VERSION "HIPBNYYYYYYYYYYYYYYYYYYYYYYYYYYYYYYYYYYYYY/4/%%%/4/'%**4YYY///"

NS_ :

BS_:

BU_: GTW IMU TMS SCH BMS0 BMS1 BMS2 BMS3 BMS4 BMS5 BMS6

BO_ 16 GTW_requests: 1 GTW
 SG_ transmit_request : 0|1@1+ (1,0) [0|0] ""  BMS0
 SG_ BMS_state_request : 1|1@1+ (1,0) [0|0] ""  BMS0

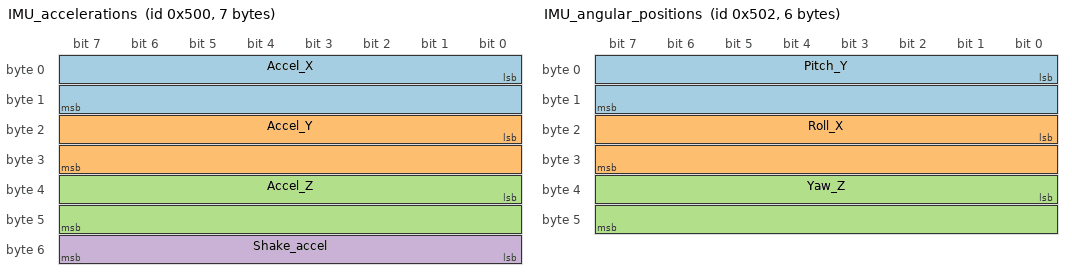
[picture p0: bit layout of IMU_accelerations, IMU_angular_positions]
BO_ 1280 IMU_accelerations: 7 IMU
 SG_ Accel_X : 0|16@1- (1,0) [-2000|2000] "mG"  GTW
 SG_ Accel_Y : 16|16@1- (1,0) [-2000|2000] "mG"  GTW
 SG_ Accel_Z : 32|16@1- (1,0) [-2000|2000] "mG"  GTW
 SG_ Shake_accel : 48|8@1+ (1,0) [0|1] ""  GTW

BO_ 1282 IMU_angular_positions: 6 IMU
 SG_ Pitch_Y : 0|16@1- (1,0) [-180|180] "Degrees"  GTW
 SG_ Roll_X : 16|16@1- (1,0) [-90|90] "Degrees"  GTW
 SG_ Yaw_Z : 32|16@1+ (1,0) [0|360] "Degrees"  GTW

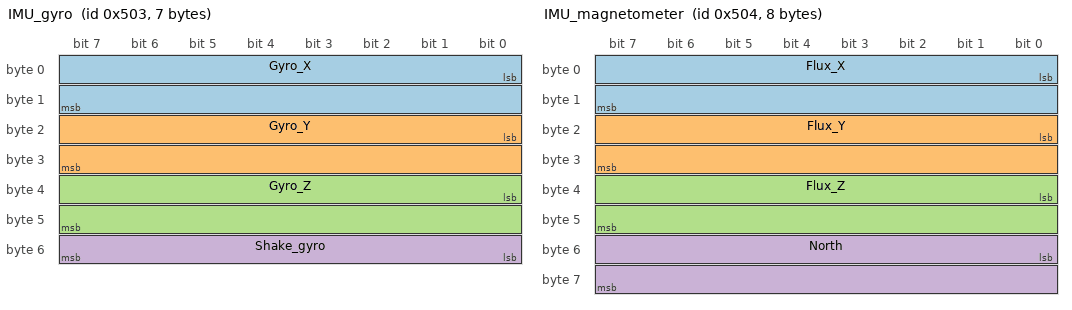
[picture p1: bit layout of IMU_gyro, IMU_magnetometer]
BO_ 1283 IMU_gyro: 7 IMU
 SG_ Gyro_X : 0|16@1- (1,0) [-2000|2000] "deg/Sec"  GTW
 SG_ Gyro_Y : 16|16@1- (1,0) [-2000|2000] "deg/Sec"  GTW
 SG_ Gyro_Z : 32|16@1- (1,0) [-2000|2000] "deg/Sec"  GTW
 SG_ Shake_gyro : 48|8@1+ (1,0) [0|1] ""  GTW

BO_ 1284 IMU_magnetometer: 8 IMU
 SG_ Flux_X : 0|16@1- (1,0) [-1300|1300] "uT"  GTW
 SG_ Flux_Y : 16|16@1- (1,0) [-1300|1300] "uT"  GTW
 SG_ Flux_Z : 32|16@1- (1,0) [-2500|2500] "uT"  GTW
 SG_ North : 48|16@1+ (1,0) [0|360] "deg"  GTW

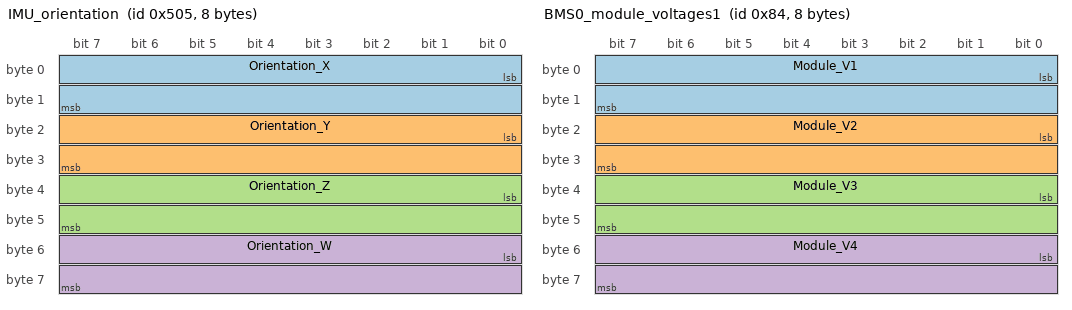
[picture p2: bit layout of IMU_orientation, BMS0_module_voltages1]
BO_ 1285 IMU_orientation: 8 IMU
 SG_ Orientation_X : 0|16@1- (1,0) [-1|1] ""  GTW
 SG_ Orientation_Y : 16|16@1- (1,0) [-1|1] ""  GTW
 SG_ Orientation_Z : 32|16@1- (1,0) [-1|1] ""  GTW
 SG_ Orientation_W : 48|16@1- (1,0) [-1|1] ""  GTW

BO_ 1281 IMU_altimeter: 4 IMU
 SG_ Altitude : 0|20@1- (1,0) [-698|11775] "m"  GTW
 SG_ IMU_ambient_temp : 20|12@1- (1,0) [-40|85] "degC"  GTW

BO_ 132 BMS0_module_voltages1: 8 BMS0
 SG_ Module_V1 : 0|16@1+ (1,0) [0|5000] "mV"  GTW
 SG_ Module_V2 : 16|16@1+ (1,0) [0|5000] "mV"  GTW
 SG_ Module_V3 : 32|16@1+ (1,0) [0|5000] "mV"  GTW
 SG_ Module_V4 : 48|16@1+ (1,0) [0|5000] "mV"  GTW

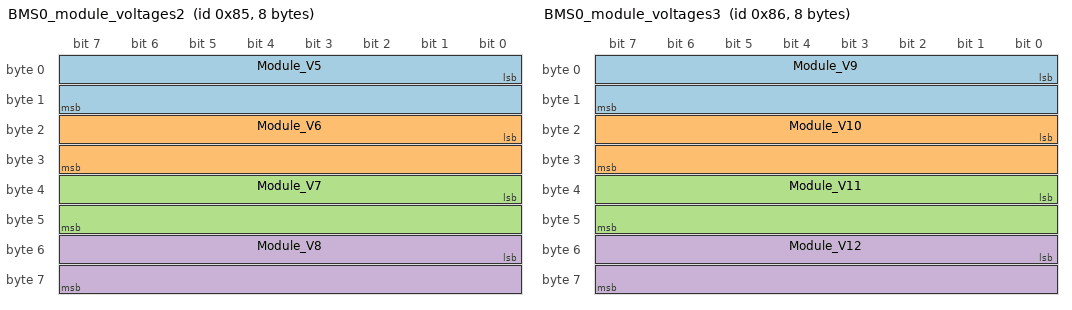
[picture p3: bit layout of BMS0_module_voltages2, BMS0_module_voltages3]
BO_ 133 BMS0_module_voltages2: 8 BMS0
 SG_ Module_V5 : 0|16@1+ (1,0) [0|5000] "mV"  GTW
 SG_ Module_V6 : 16|16@1+ (1,0) [0|5000] "mV"  GTW
 SG_ Module_V7 : 32|16@1+ (1,0) [0|5000] "mV"  GTW
 SG_ Module_V8 : 48|16@1+ (1,0) [0|5000] "mV"  GTW

BO_ 134 BMS0_module_voltages3: 8 BMS0
 SG_ Module_V9 : 0|16@1+ (1,0) [0|5000] "mV"  GTW
 SG_ Module_V10 : 16|16@1+ (1,0) [0|5000] "mV"  GTW
 SG_ Module_V11 : 32|16@1+ (1,0) [0|5000] "mV"  GTW
 SG_ Module_V12 : 48|16@1+ (1,0) [0|5000] "mV"  GTW

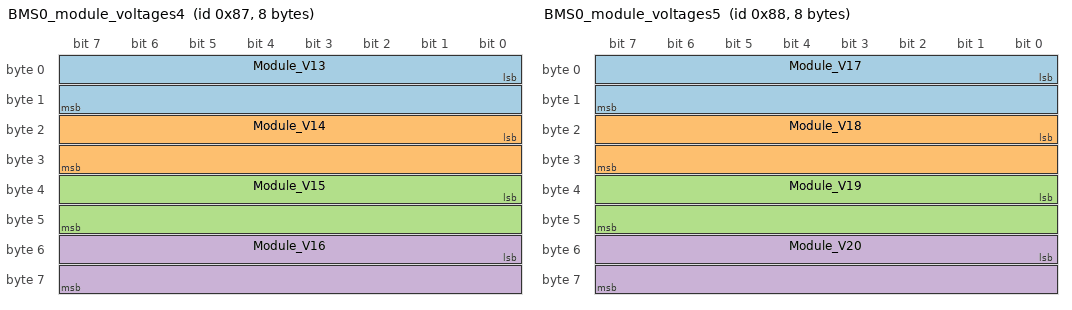
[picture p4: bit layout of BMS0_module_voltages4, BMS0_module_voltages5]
BO_ 135 BMS0_module_voltages4: 8 BMS0
 SG_ Module_V13 : 0|16@1+ (1,0) [0|5000] "mV"  GTW
 SG_ Module_V14 : 16|16@1+ (1,0) [0|5000] "mV"  GTW
 SG_ Module_V15 : 32|16@1+ (1,0) [0|5000] "mV"  GTW
 SG_ Module_V16 : 48|16@1+ (1,0) [0|5000] "mV"  GTW

BO_ 136 BMS0_module_voltages5: 8 BMS0
 SG_ Module_V17 : 0|16@1+ (1,0) [0|5000] "mV"  GTW
 SG_ Module_V18 : 16|16@1+ (1,0) [0|5000] "mV"  GTW
 SG_ Module_V19 : 32|16@1+ (1,0) [0|5000] "mV"  GTW
 SG_ Module_V20 : 48|16@1+ (1,0) [0|5000] "mV"  GTW

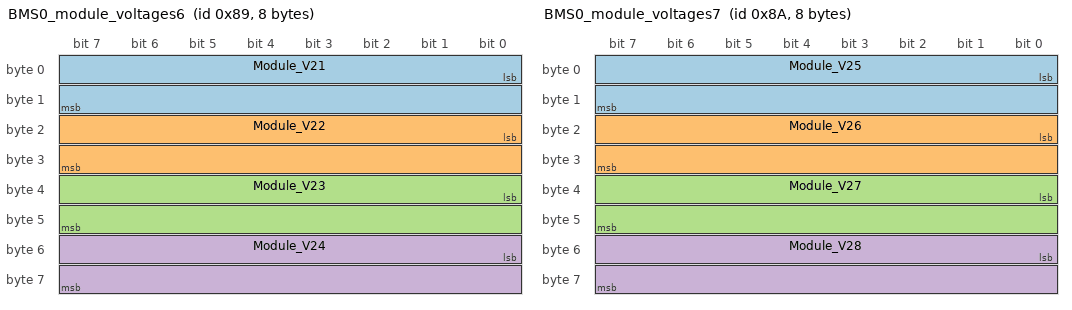
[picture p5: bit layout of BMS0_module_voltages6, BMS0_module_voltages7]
BO_ 137 BMS0_module_voltages6: 8 BMS0
 SG_ Module_V21 : 0|16@1+ (1,0) [0|5000] "mV"  GTW
 SG_ Module_V22 : 16|16@1+ (1,0) [0|5000] "mV"  GTW
 SG_ Module_V23 : 32|16@1+ (1,0) [0|5000] "mV"  GTW
 SG_ Module_V24 : 48|16@1+ (1,0) [0|5000] "mV"  GTW

BO_ 138 BMS0_module_voltages7: 8 BMS0
 SG_ Module_V25 : 0|16@1+ (1,0) [0|5000] "mV"  GTW
 SG_ Module_V26 : 16|16@1+ (1,0) [0|5000] "mV"  GTW
 SG_ Module_V27 : 32|16@1+ (1,0) [0|5000] "mV"  GTW
 SG_ Module_V28 : 48|16@1+ (1,0) [0|5000] "mV"  GTW

BO_ 139 BMS0_module_voltages8: 4 BMS0
 SG_ Module_V29 : 0|16@1+ (1,0) [0|5000] "mV"  GTW
 SG_ Module_V30 : 16|16@1+ (1,0) [0|5000] "mV"  GTW

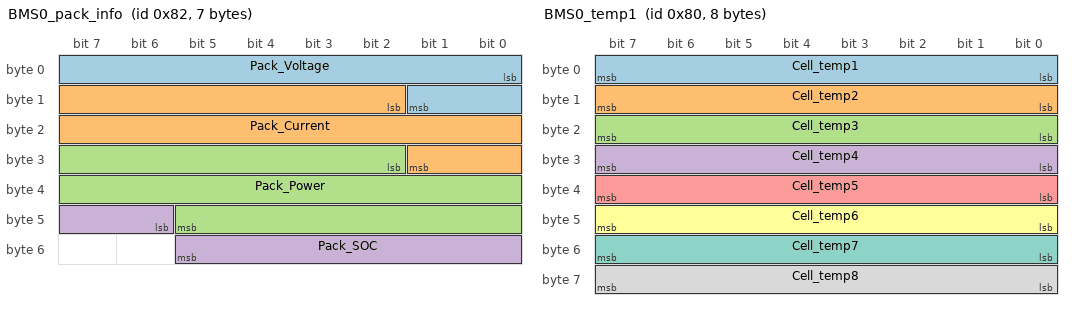
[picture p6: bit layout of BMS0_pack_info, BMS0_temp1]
BO_ 130 BMS0_pack_info: 7 BMS0
 SG_ Pack_Voltage : 0|10@1+ (1,0) [50|500] "V"  GTW
 SG_ Pack_Current : 10|16@1- (1,0) [-1000|1000] "A"  GTW
 SG_ Pack_Power : 26|20@1- (1,0) [-200000|200000] "W"  GTW
 SG_ Pack_SOC : 46|8@1+ (1,0) [0|100] "%"  GTW

BO_ 128 BMS0_temp1: 8 BMS0
 SG_ Cell_temp1 : 0|8@1+ (1,0) [0|255] "degC"  GTW
 SG_ Cell_temp2 : 8|8@1+ (1,0) [0|255] "degC"  GTW
 SG_ Cell_temp3 : 16|8@1+ (1,0) [0|255] "degC"  GTW
 SG_ Cell_temp4 : 24|8@1+ (1,0) [0|255] "degC"  GTW
 SG_ Cell_temp5 : 32|8@1+ (1,0) [0|255] "degC"  GTW
 SG_ Cell_temp6 : 40|8@1+ (1,0) [0|255] "degC"  GTW
 SG_ Cell_temp7 : 48|8@1+ (1,0) [0|255] "degC"  GTW
 SG_ Cell_temp8 : 56|8@1+ (1,0) [0|255] "degC"  GTW

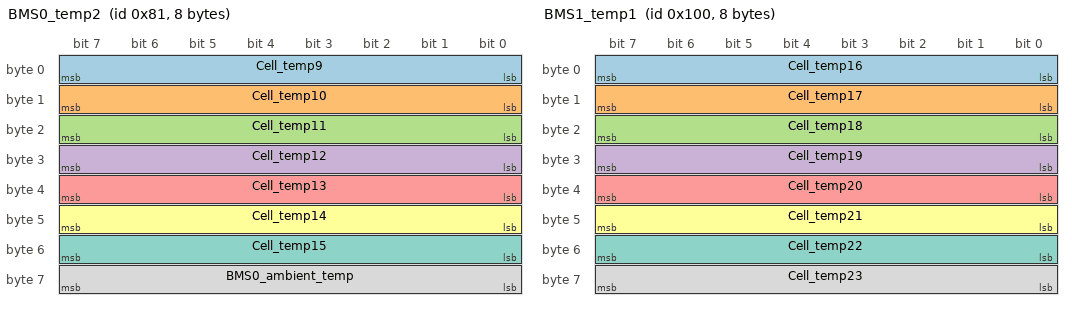
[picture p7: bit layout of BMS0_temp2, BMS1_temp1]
BO_ 129 BMS0_temp2: 8 BMS0
 SG_ Cell_temp9 : 0|8@1+ (1,0) [0|255] "degC"  GTW
 SG_ Cell_temp10 : 8|8@1+ (1,0) [0|255] "degC"  GTW
 SG_ Cell_temp11 : 16|8@1+ (1,0) [0|255] "degC"  GTW
 SG_ Cell_temp12 : 24|8@1+ (1,0) [0|255] "degC"  GTW
 SG_ Cell_temp13 : 32|8@1+ (1,0) [0|255] "degC"  GTW
 SG_ Cell_temp14 : 40|8@1+ (1,0) [0|255] "degC"  GTW
 SG_ Cell_temp15 : 48|8@1+ (1,0) [0|255] "degC"  GTW
 SG_ BMS0_ambient_temp : 56|8@1- (1,0) [-40|85] "degC"  GTW

BO_ 256 BMS1_temp1: 8 BMS1
 SG_ Cell_temp16 : 0|8@1+ (1,0) [0|255] "degC"  GTW
 SG_ Cell_temp17 : 8|8@1+ (1,0) [0|255] "degC"  GTW
 SG_ Cell_temp18 : 16|8@1+ (1,0) [0|255] "degC"  GTW
 SG_ Cell_temp19 : 24|8@1+ (1,0) [0|255] "degC"  GTW
 SG_ Cell_temp20 : 32|8@1+ (1,0) [0|255] "degC"  GTW
 SG_ Cell_temp21 : 40|8@1+ (1,0) [0|255] "degC"  GTW
 SG_ Cell_temp22 : 48|8@1+ (1,0) [0|255] "degC"  GTW
 SG_ Cell_temp23 : 56|8@1+ (1,0) [0|255] "degC"  GTW

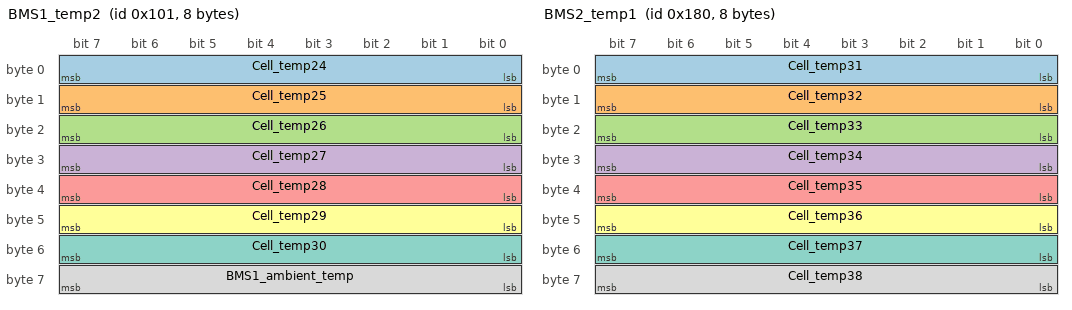
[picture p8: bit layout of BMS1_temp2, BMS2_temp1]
BO_ 257 BMS1_temp2: 8 BMS1
 SG_ Cell_temp24 : 0|8@1+ (1,0) [0|255] "degC"  GTW
 SG_ Cell_temp25 : 8|8@1+ (1,0) [0|255] "degC"  GTW
 SG_ Cell_temp26 : 16|8@1+ (1,0) [0|255] "degC"  GTW
 SG_ Cell_temp27 : 24|8@1+ (1,0) [0|255] "degC"  GTW
 SG_ Cell_temp28 : 32|8@1+ (1,0) [0|255] "degC"  GTW
 SG_ Cell_temp29 : 40|8@1+ (1,0) [0|255] "degC"  GTW
 SG_ Cell_temp30 : 48|8@1+ (1,0) [0|255] "degC"  GTW
 SG_ BMS1_ambient_temp : 56|8@1- (1,0) [-40|85] "degC"  GTW

BO_ 384 BMS2_temp1: 8 BMS2
 SG_ Cell_temp31 : 0|8@1+ (1,0) [0|255] "degC"  GTW
 SG_ Cell_temp32 : 8|8@1+ (1,0) [0|255] "degC"  GTW
 SG_ Cell_temp33 : 16|8@1+ (1,0) [0|255] "degC"  GTW
 SG_ Cell_temp34 : 24|8@1+ (1,0) [0|255] "degC"  GTW
 SG_ Cell_temp35 : 32|8@1+ (1,0) [0|255] "degC"  GTW
 SG_ Cell_temp36 : 40|8@1+ (1,0) [0|255] "degC"  GTW
 SG_ Cell_temp37 : 48|8@1+ (1,0) [0|255] "degC"  GTW
 SG_ Cell_temp38 : 56|8@1+ (1,0) [0|255] "degC"  GTW

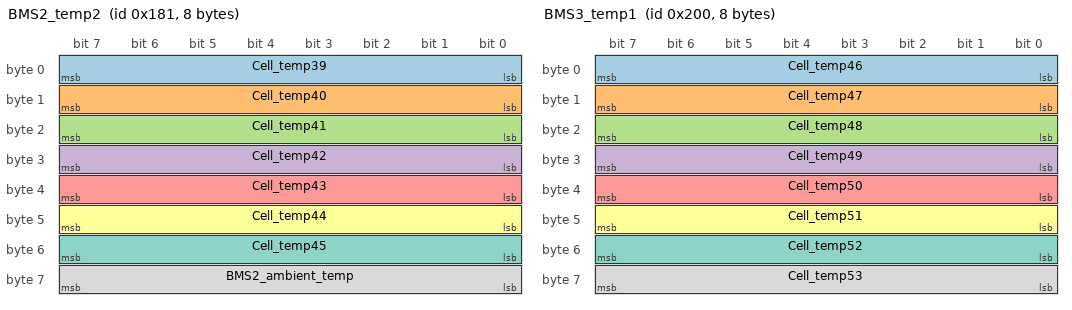
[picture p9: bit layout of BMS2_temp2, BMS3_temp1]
BO_ 385 BMS2_temp2: 8 BMS2
 SG_ Cell_temp39 : 0|8@1+ (1,0) [0|255] "degC"  GTW
 SG_ Cell_temp40 : 8|8@1+ (1,0) [0|255] "degC"  GTW
 SG_ Cell_temp41 : 16|8@1+ (1,0) [0|255] "degC"  GTW
 SG_ Cell_temp42 : 24|8@1+ (1,0) [0|255] "degC"  GTW
 SG_ Cell_temp43 : 32|8@1+ (1,0) [0|255] "degC"  GTW
 SG_ Cell_temp44 : 40|8@1+ (1,0) [0|255] "degC"  GTW
 SG_ Cell_temp45 : 48|8@1+ (1,0) [0|255] "degC"  GTW
 SG_ BMS2_ambient_temp : 56|8@1- (1,0) [-40|85] "degC"  GTW

BO_ 512 BMS3_temp1: 8 BMS3
 SG_ Cell_temp46 : 0|8@1+ (1,0) [0|255] "degC"  GTW
 SG_ Cell_temp47 : 8|8@1+ (1,0) [0|255] "degC"  GTW
 SG_ Cell_temp48 : 16|8@1+ (1,0) [0|255] "degC"  GTW
 SG_ Cell_temp49 : 24|8@1+ (1,0) [0|255] "degC"  GTW
 SG_ Cell_temp50 : 32|8@1+ (1,0) [0|255] "degC"  GTW
 SG_ Cell_temp51 : 40|8@1+ (1,0) [0|255] "degC"  GTW
 SG_ Cell_temp52 : 48|8@1+ (1,0) [0|255] "degC"  GTW
 SG_ Cell_temp53 : 56|8@1+ (1,0) [0|255] "degC"  GTW

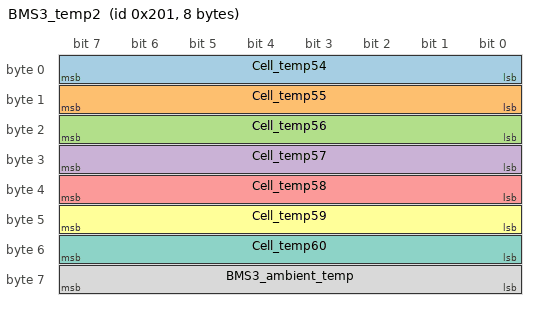
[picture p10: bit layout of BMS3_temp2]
BO_ 513 BMS3_temp2: 8 BMS3
 SG_ Cell_temp54 : 0|8@1+ (1,0) [0|255] "degC"  GTW
 SG_ Cell_temp55 : 8|8@1+ (1,0) [0|255] "degC"  GTW
 SG_ Cell_temp56 : 16|8@1+ (1,0) [0|255] "degC"  GTW
 SG_ Cell_temp57 : 24|8@1+ (1,0) [0|255] "degC"  GTW
 SG_ Cell_temp58 : 32|8@1+ (1,0) [0|255] "degC"  GTW
 SG_ Cell_temp59 : 40|8@1+ (1,0) [0|255] "degC"  GTW
 SG_ Cell_temp60 : 48|8@1+ (1,0) [0|255] "degC"  GTW
 SG_ BMS3_ambient_temp : 56|8@1- (1,0) [-40|85] "degC"  GTW

BO_ 131 BMS0_module_discharge: 4 BMS0
 SG_ Module_Discharge_1 : 0|1@1+ (1,0) [0|1] "Bool"  GTW
 SG_ Module_Discharge_2 : 1|1@1+ (1,0) [0|1] "Bool"  GTW
 SG_ Module_Discharge_3 : 2|1@1+ (1,0) [0|1] "Bool"  GTW
 SG_ Module_Discharge_4 : 3|1@1+ (1,0) [0|1] "Bool"  GTW
 SG_ Module_Discharge_5 : 4|1@1+ (1,0) [0|1] "Bool"  GTW
 SG_ Module_Discharge_6 : 5|1@1+ (1,0) [0|1] "Bool"  GTW
 SG_ Module_Discharge_7 : 6|1@1+ (1,0) [0|1] "Bool"  GTW
 SG_ Module_Discharge_8 : 7|1@1+ (1,0) [0|1] "Bool"  GTW
 SG_ Module_Discharge_9 : 8|1@1+ (1,0) [0|1] "Bool"  GTW
 SG_ Module_Discharge_10 : 9|1@1+ (1,0) [0|1] "Bool"  GTW
 SG_ Module_Discharge_11 : 10|1@1+ (1,0) [0|1] "Bool"  GTW
 SG_ Module_Discharge_12 : 11|1@1+ (1,0) [0|1] "Bool"  GTW
 SG_ Module_Discharge_13 : 12|1@1+ (1,0) [0|1] "Bool"  GTW
 SG_ Module_Discharge_14 : 13|1@1+ (1,0) [0|1] "Bool"  GTW
 SG_ Module_Discharge_15 : 14|1@1+ (1,0) [0|1] "Bool"  GTW
 SG_ Module_Discharge_16 : 15|1@1+ (1,0) [0|1] "Bool"  GTW
 SG_ Module_Discharge_17 : 16|1@1+ (1,0) [0|1] "Bool"  GTW
 SG_ Module_Discharge_18 : 17|1@1+ (1,0) [0|1] "Bool"  GTW
 SG_ Module_Discharge_19 : 18|1@1+ (1,0) [0|1] "Bool"  GTW
 SG_ Module_Discharge_20 : 19|1@1+ (1,0) [0|1] "Bool"  GTW
 SG_ Module_Discharge_21 : 20|1@1+ (1,0) [0|1] "Bool"  GTW
 SG_ Module_Discharge_22 : 21|1@1+ (1,0) [0|1] "Bool"  GTW
 SG_ Module_Discharge_23 : 22|1@1+ (1,0) [0|1] "Bool"  GTW
 SG_ Module_Discharge_24 : 23|1@1+ (1,0) [0|1] "Bool"  GTW
 SG_ Module_Discharge_25 : 24|1@1+ (1,0) [0|1] "Bool"  GTW
 SG_ Module_Discharge_26 : 25|1@1+ (1,0) [0|1] "Bool"  GTW
 SG_ Module_Discharge_27 : 26|1@1+ (1,0) [0|1] "Bool"  GTW
 SG_ Module_Discharge_28 : 27|1@1+ (1,0) [0|1] "Bool"  GTW
 SG_ Module_Discharge_29 : 28|1@1+ (1,0) [0|1] "Bool"  GTW
 SG_ Module_Discharge_30 : 29|1@1+ (1,0) [0|1] "Bool"  GTW

CM_ SG_ 16 transmit_request "The requested network state of the GTW. If this is set quiet all of the other devices will not transmit messages, if it is set to transmit, they will all transmit their regular messages";
CM_ SG_ 16 BMS_state_request "This is how the GTW can request that the BMSs go into stacked or independent mode";
CM_ SG_ 1285 Orientation_X "Orientation in Quaternion space";
CM_ SG_ 1285 Orientation_Y "Orientation in Quaternion space";
CM_ SG_ 1285 Orientation_Z "Orientation in Quaternion space";
CM_ SG_ 1285 Orientation_W "Orientation in Quaternion space";
BA_DEF_ BO_  "GenMsgCycleTime" INT 0 1000000;
BA_DEF_DEF_  "GenMsgCycleTime" 0;
BA_ "GenMsgCycleTime" BO_ 16 10;
BA_ "GenMsgCycleTime" BO_ 1280 100;
BA_ "GenMsgCycleTime" BO_ 1282 100;
BA_ "GenMsgCycleTime" BO_ 1283 100;
BA_ "GenMsgCycleTime" BO_ 1284 100;
BA_ "GenMsgCycleTime" BO_ 1285 100;
BA_ "GenMsgCycleTime" BO_ 1281 10;
BA_ "GenMsgCycleTime" BO_ 132 100;
BA_ "GenMsgCycleTime" BO_ 133 100;
BA_ "GenMsgCycleTime" BO_ 134 100;
BA_ "GenMsgCycleTime" BO_ 135 100;
BA_ "GenMsgCycleTime" BO_ 136 100;
BA_ "GenMsgCycleTime" BO_ 137 100;
BA_ "GenMsgCycleTime" BO_ 130 100;
BA_ "GenMsgCycleTime" BO_ 128 1;
BA_ "GenMsgCycleTime" BO_ 129 1;
BA_ "GenMsgCycleTime" BO_ 256 1;
BA_ "GenMsgCycleTime" BO_ 257 1;
BA_ "GenMsgCycleTime" BO_ 384 1;
BA_ "GenMsgCycleTime" BO_ 385 1;
BA_ "GenMsgCycleTime" BO_ 512 1;
BA_ "GenMsgCycleTime" BO_ 513 1;
BA_ "GenMsgCycleTime" BO_ 131 1;
VAL_ 16 transmit_request 0 "network_quiet" 1 "network_transmit" ;
VAL_ 16 BMS_state_request 0 "BMS_Independent" 1 "BMS_Stacked" ;
VAL_ 1280 Shake_accel 0 "no_shake_detected" 1 "shake_detected" ;
VAL_ 1283 Shake_gyro 0 "no_shake_detected" 1 "shake_detected" ;
VAL_ 131 Module_Discharge_1 0 "Idle" 1 "Discharging" ;
VAL_ 131 Module_Discharge_2 0 "Idle" 1 "Discharging" ;
VAL_ 131 Module_Discharge_3 0 "Idle" 1 "Discharging" ;
VAL_ 131 Module_Discharge_4 0 "Idle" 1 "Discharging" ;
VAL_ 131 Module_Discharge_5 0 "Idle" 1 "Discharging" ;
VAL_ 131 Module_Discharge_6 0 "Idle" 1 "Discharging" ;
VAL_ 131 Module_Discharge_7 0 "Idle" 1 "Discharging" ;
VAL_ 131 Module_Discharge_8 0 "Idle" 1 "Discharging" ;
VAL_ 131 Module_Discharge_9 0 "Idle" 1 "Discharging" ;
VAL_ 131 Module_Discharge_10 0 "Idle" 1 "Discharging" ;
VAL_ 131 Module_Discharge_11 0 "Idle" 1 "Discharging" ;
VAL_ 131 Module_Discharge_12 0 "Idle" 1 "Discharging" ;
VAL_ 131 Module_Discharge_13 0 "Idle" 1 "Discharging" ;
VAL_ 131 Module_Discharge_14 0 "Idle" 1 "Discharging" ;
VAL_ 131 Module_Discharge_15 0 "Idle" 1 "Discharging" ;
VAL_ 131 Module_Discharge_16 0 "Idle" 1 "Discharging" ;
VAL_ 131 Module_Discharge_17 0 "Idle" 1 "Discharging" ;
VAL_ 131 Module_Discharge_18 0 "Idle" 1 "Discharging" ;
VAL_ 131 Module_Discharge_19 0 "Idle" 1 "Discharging" ;
VAL_ 131 Module_Discharge_20 0 "Idle" 1 "Discharging" ;
VAL_ 131 Module_Discharge_21 0 "Idle" 1 "Discharging" ;
VAL_ 131 Module_Discharge_22 0 "Idle" 1 "Discharging" ;
VAL_ 131 Module_Discharge_23 0 "Idle" 1 "Discharging" ;
VAL_ 131 Module_Discharge_24 0 "Idle" 1 "Discharging" ;
VAL_ 131 Module_Discharge_25 0 "Idle" 1 "Discharging" ;
VAL_ 131 Module_Discharge_26 0 "Idle" 1 "Discharging" ;
VAL_ 131 Module_Discharge_27 0 "Idle" 1 "Discharging" ;
VAL_ 131 Module_Discharge_28 0 "Idle" 1 "Discharging" ;
VAL_ 131 Module_Discharge_29 0 "Idle" 1 "Discharging" ;
VAL_ 131 Module_Discharge_30 0 "Idle" 1 "Discharging" ;
